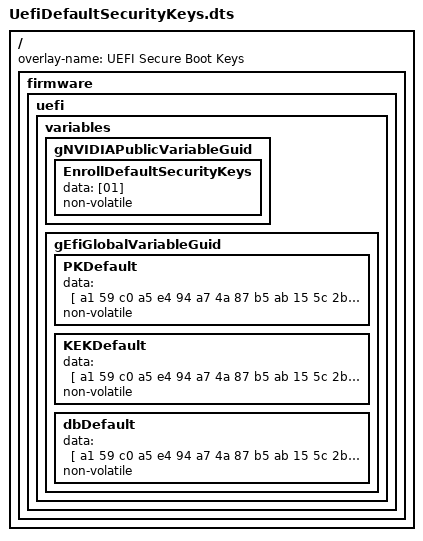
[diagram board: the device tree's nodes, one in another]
/** @file
*
*  Copyright (c) 2023, NVIDIA CORPORATION & AFFILIATES. All rights reserved.
*
*  SPDX-License-Identifier: BSD-2-Clause-Patent
*
**/
/dts-v1/;
/plugin/;
/ {
    overlay-name = "UEFI Secure Boot Keys";
    fragment@0 {
        target-path = "/";
        board_config {
            sw-modules = "uefi";
        };
        __overlay__ {
            firmware {
                uefi {
                    variables {
                        gNVIDIAPublicVariableGuid {
                            EnrollDefaultSecurityKeys {
                                data = [01];
                                non-volatile;
                            };
                        };
                        gEfiGlobalVariableGuid {
                            PKDefault {
                                data = [
 a1 59 c0 a5 e4 94 a7 4a 87 b5 ab 15 5c 2b f0 72
 49 03 00 00 00 00 00 00 2d 03 00 00 da 84 00 ee
 b6 30 6a 48 b9 b4 d8 10 9c 4b 51 21 30 82 03 19
 30 82 02 01 a0 03 02 01 02 02 14 23 b3 eb 03 c1
 76 06 ab dc ac a5 09 25 4c 3b 5f ee 77 9c 3c 30
 0d 06 09 2a 86 48 86 f7 0d 01 01 0b 05 00 30 1c
 31 1a 30 18 06 03 55 04 03 0c 11 4e 6f 6f 62 20
 50 6c 61 74 66 6f 72 6d 20 4b 65 79 30 1e 17 0d
 32 36 30 35 30 33 31 34 33 30 31 36 5a 17 0d 33
 36 30 34 33 30 31 34 33 30 31 36 5a 30 1c 31 1a
 30 18 06 03 55 04 03 0c 11 4e 6f 6f 62 20 50 6c
 61 74 66 6f 72 6d 20 4b 65 79 30 82 01 22 30 0d
 06 09 2a 86 48 86 f7 0d 01 01 01 05 00 03 82 01
 0f 00 30 82 01 0a 02 82 01 01 00 d2 66 da 04 90
 60 06 22 c6 c7 86 8f 3f 70 e8 04 f9 8a 55 e7 61
 98 74 93 7e 84 1c 29 98 27 70 31 66 c8 f6 50 54
 2d 47 d2 bc d8 2f 97 ea a3 d8 37 67 f9 31 7d 2a
 fc e8 7f f4 03 c2 41 ac 2c ee 02 c8 0e 3d b4 e5
 75 69 b4 15 8b cd 4d bc 04 f2 c7 15 8c b0 e3 30
 33 a2 d8 3a 77 1e b6 fe 5f 28 e7 5f 11 0e 53 71
 d0 aa d7 0d 21 1f 99 ba 5c 68 00 ee 5a 67 f2 5d
 a8 17 33 79 1f a8 61 29 6f da 71 60 94 7a 60 e2
 4d cd 98 c0 d9 e6 fe d2 17 d0 d5 be 4d d9 3c 82
 31 2a 14 fa eb 4c ff 08 1e dc f5 0f ae 36 f7 51
 86 46 18 dc 98 20 fe d9 e2 49 c7 52 2d 9f ac 87
 4f aa 0e c4 e0 15 24 95 06 80 b0 0f 45 52 6f c2
 9f 97 58 9d de 3d 69 d8 04 1b 94 ae 63 1d 5f 6f
 5e b4 13 a4 b6 d0 b3 e0 26 9a 37 3b 64 8f fc 10
 7c cd 79 74 76 cb a1 25 a5 ee 40 c2 fb b9 22 50
 fd 96 ef e0 4e 76 88 af 91 a9 b5 02 03 01 00 01
 a3 53 30 51 30 1d 06 03 55 1d 0e 04 16 04 14 2c
 b2 34 b0 45 06 12 fc 43 c5 42 d1 da aa 3b e2 a8
 25 1f ae 30 1f 06 03 55 1d 23 04 18 30 16 80 14
 2c b2 34 b0 45 06 12 fc 43 c5 42 d1 da aa 3b e2
 a8 25 1f ae 30 0f 06 03 55 1d 13 01 01 ff 04 05
 30 03 01 01 ff 30 0d 06 09 2a 86 48 86 f7 0d 01
 01 0b 05 00 03 82 01 01 00 2d 4a b1 95 ae 54 cc
 f6 bd 2d 67 64 11 47 99 49 74 3c 62 eb 63 90 fa
 fb be 49 59 72 c2 70 95 a8 67 d3 dd 44 59 e0 c3
 f1 a2 d8 bd e2 a4 85 82 97 8d 0a d6 3d 1d 78 33
 50 1e 5f 73 8d 74 55 af 61 6e fc f7 11 8c 46 34
 b2 46 d0 ba 0c a2 72 f6 0b 86 12 68 ed 45 49 3e
 ad 24 d2 07 51 db 90 e9 c4 8c eb 93 ec ff 3d 34
 9c d2 14 cb fb 66 e9 c0 b9 c6 77 4b bc 50 3b 22
 b1 e1 54 ee 14 b0 59 68 c4 4c 89 c0 bf 81 d8 e9
 7f 1b 9e 22 08 a6 d2 c5 f8 f0 d9 31 5e f5 82 b2
 33 f9 21 b0 93 13 6b 66 b1 69 ea d1 d5 1a 0b 5b
 db b2 6e f4 d3 7b d9 8d 90 65 92 4c 11 5e ad 52
 4d e4 93 2a 8a 86 e5 1f 70 b9 c1 72 eb eb a2 ad
 03 8e d5 16 79 b9 d7 70 61 33 12 43 db 86 09 4a
 f4 4d 6d d1 ee ba 5e 59 c8 d7 14 93 81 f7 b2 ac
 df 47 aa a9 5c b3 24 10 e0 17 0e 03 67 7c 9d 16
 49 ab ff 6b c3 b5 53 3a 55
                                ];
                                non-volatile;
                            };
                            KEKDefault {
                                data = [
 a1 59 c0 a5 e4 94 a7 4a 87 b5 ab 15 5c 2b f0 72
 51 03 00 00 00 00 00 00 35 03 00 00 da 84 00 ee
 b6 30 6a 48 b9 b4 d8 10 9c 4b 51 21 30 82 03 21
 30 82 02 09 a0 03 02 01 02 02 14 60 20 7e 3d a5
 e5 0a 19 d7 74 30 42 7b 8f 92 8f bd 69 50 f7 30
 0d 06 09 2a 86 48 86 f7 0d 01 01 0b 05 00 30 20
 31 1e 30 1c 06 03 55 04 03 0c 15 4e 6f 6f 62 20
 4b 65 79 20 45 78 63 68 61 6e 67 65 20 4b 65 79
 30 1e 17 0d 32 36 30 35 30 33 31 34 33 30 34 36
 5a 17 0d 33 36 30 34 33 30 31 34 33 30 34 36 5a
 30 20 31 1e 30 1c 06 03 55 04 03 0c 15 4e 6f 6f
 62 20 4b 65 79 20 45 78 63 68 61 6e 67 65 20 4b
 65 79 30 82 01 22 30 0d 06 09 2a 86 48 86 f7 0d
 01 01 01 05 00 03 82 01 0f 00 30 82 01 0a 02 82
 01 01 00 c7 86 bc a3 e4 9c 43 98 ee 68 c8 f2 78
 a4 78 0f c8 9d 5c 87 58 65 f2 43 68 70 2c 76 ee
 99 ff 48 76 16 f8 12 25 1b aa 44 46 c8 f5 c4 35
 b2 9d c6 30 2d 64 dd 6b 39 d6 3b d6 9f 06 95 a2
 e8 0c f3 ce ac 0a 35 6d 72 4f e3 0e b1 1e 77 4f
 1d e8 0d 18 18 df c9 c9 77 ab b1 e5 e7 ce 49 87
 e2 b0 07 ec 06 1b 14 a4 8d 35 29 bd 74 24 93 ea
 b9 c1 7e 32 9e 5e b8 20 02 eb 85 cd f0 d7 1f d6
 1a 33 4c c7 2c 40 c4 b7 77 2d 7f 0c c5 28 c5 aa
 5d 8c d6 88 65 cb 5b 89 b3 8f 25 47 a7 34 66 31
 86 8b c7 fb 5c f3 4e d6 22 70 b4 c4 38 50 38 68
 17 72 00 73 2e 1a 87 32 28 89 bd 3d bd af 0b c6
 16 aa 83 e2 f2 5b 92 d0 af 85 e8 13 bc fb 34 e8
 39 53 e9 9c 6f 24 72 fb fc 54 68 ea 00 1e 13 70
 73 ba ab 50 ff fe 2e e9 5a f0 16 a7 7c 01 3a 92
 5f 42 95 b2 2f ca 1b 3f 00 39 55 e4 65 48 4f f8
 da 5e 33 02 03 01 00 01 a3 53 30 51 30 1d 06 03
 55 1d 0e 04 16 04 14 62 5c 6c 1d 04 06 86 d0 a1
 d3 97 d6 d6 b8 dd 79 33 ca ed 6a 30 1f 06 03 55
 1d 23 04 18 30 16 80 14 62 5c 6c 1d 04 06 86 d0
 a1 d3 97 d6 d6 b8 dd 79 33 ca ed 6a 30 0f 06 03
 55 1d 13 01 01 ff 04 05 30 03 01 01 ff 30 0d 06
 09 2a 86 48 86 f7 0d 01 01 0b 05 00 03 82 01 01
 00 42 05 97 59 ff 7b 21 e9 99 4b 20 df 1b ea e8
 81 5d 5b 16 40 33 28 a4 eb a4 f1 90 68 2c 2a 6b
 66 5c f1 eb 4c 07 4f dd db 36 8a 9b b6 5e fd 7c
 60 8a 6f 90 e3 41 8d 77 79 6e 67 4f 50 5f bf 07
 7d 00 ba 72 a7 7a 7a 03 a4 81 22 18 2f 41 d0 95
 6c 3a 73 f9 65 94 b6 c5 90 3b a4 58 2b e2 8d d3
 d9 79 7e e1 46 7d f2 d2 76 50 65 a1 c6 9f 1a 8f
 c1 7e 60 82 b9 7b df a3 4c 6d 45 36 e5 ec d0 c0
 73 c2 88 4c 38 0e ab e1 d3 48 33 5d 33 15 00 16
 b2 67 50 d8 a8 81 84 28 85 bc ff 33 59 0b d6 ff
 34 05 3e f7 ff 5b 21 3a ff 96 08 e9 93 b5 de 5e
 0a 9a ed e4 c8 d5 07 31 8f 26 9c ee 99 e1 e1 f2
 f1 70 3e 66 4f 57 91 a7 4e 26 01 3c da 77 1a 9b
 16 99 f2 d3 1c 5d 3d b0 e3 e3 28 73 75 3f ac f1
 dd e7 04 4e f0 ab a7 9a 25 99 70 09 e6 55 78 03
 a1 63 ac c0 63 a9 e2 0e 64 ed 01 2b e9 63 6b 06
 cd
                                ];
                                non-volatile;
                            };
                            dbDefault {
                                data = [
 a1 59 c0 a5 e4 94 a7 4a 87 b5 ab 15 5c 2b f0 72
 5d 03 00 00 00 00 00 00 41 03 00 00 da 84 00 ee
 b6 30 6a 48 b9 b4 d8 10 9c 4b 51 21 30 82 03 2d
 30 82 02 15 a0 03 02 01 02 02 14 67 49 d6 ec 9d
 ea a8 f4 89 f6 e6 99 8a 87 c4 d9 e1 cb 83 87 30
 0d 06 09 2a 86 48 86 f7 0d 01 01 0b 05 00 30 26
 31 24 30 22 06 03 55 04 03 0c 1b 4e 6f 6f 62 20
 53 69 67 6e 61 74 75 72 65 20 44 61 74 61 62 61
 73 65 20 6b 65 79 30 1e 17 0d 32 36 30 35 30 33
 31 34 33 31 31 35 5a 17 0d 33 36 30 34 33 30 31
 34 33 31 31 35 5a 30 26 31 24 30 22 06 03 55 04
 03 0c 1b 4e 6f 6f 62 20 53 69 67 6e 61 74 75 72
 65 20 44 61 74 61 62 61 73 65 20 6b 65 79 30 82
 01 22 30 0d 06 09 2a 86 48 86 f7 0d 01 01 01 05
 00 03 82 01 0f 00 30 82 01 0a 02 82 01 01 00 bd
 89 4b 55 b3 de 2b fc 4d 5d a6 a7 83 c9 a3 ec e2
 27 38 d5 fd 55 5d 5d 9f 8d 23 99 4f b8 44 fd 2a
 8f f9 a7 8c 4c 23 5c f7 bb 64 6f 18 7b 48 02 91
 01 4b 9e 87 eb 0a e6 40 3c 71 57 9f e8 89 a9 54
 0b f7 11 d4 3a 2e 42 a1 1a a5 30 44 f0 b4 82 80
 d9 8e 0b 62 6b 04 42 b9 b1 b2 60 3c 83 e9 a6 f6
 7e cc 9d 22 f0 95 90 9d 6a 7c b1 ce ed e6 0f a4
 3a 80 d0 59 7c d7 06 d5 29 15 41 7d d9 ea 32 90
 2d 14 62 0b ea 8e ed 86 06 47 3f f0 03 44 46 67
 cd 85 04 7a 82 a5 3f 62 f0 fe a5 4f c2 05 0a f2
 f6 c7 61 83 6a 6d b9 d5 e4 8f b2 03 a3 f4 4b 9a
 93 62 5b 48 d9 cf ee 1c 1a cc 03 b6 f0 1a d1 61
 01 70 fa 12 3f e2 ff f7 6a 37 e0 25 47 58 15 e5
 31 41 ea fc 73 2d c8 70 eb 40 d7 74 12 c7 80 d1
 e7 8d f6 c4 f7 e5 47 34 de 00 ad 46 a6 89 90 04
 77 37 29 83 6a 72 de f8 1c 96 76 84 80 f8 89 02
 03 01 00 01 a3 53 30 51 30 1d 06 03 55 1d 0e 04
 16 04 14 97 c5 71 11 29 29 d3 82 86 c0 40 f9 2a
 ee 94 4b 30 d0 ac 04 30 1f 06 03 55 1d 23 04 18
 30 16 80 14 97 c5 71 11 29 29 d3 82 86 c0 40 f9
 2a ee 94 4b 30 d0 ac 04 30 0f 06 03 55 1d 13 01
 01 ff 04 05 30 03 01 01 ff 30 0d 06 09 2a 86 48
 86 f7 0d 01 01 0b 05 00 03 82 01 01 00 ad 5e 08
 1b 67 d4 91 87 85 b5 22 a4 05 d7 c9 77 f7 5c 25
 fc 15 0e f9 63 0b e5 60 54 9f 52 90 a9 a0 30 0d
 56 f4 54 eb 62 99 8d f9 9f 24 eb 22 6b 5e fc 3d
 e6 81 34 6f a6 99 bf 78 fd 71 12 e0 fc 2f cb 4d
 d2 1f 80 57 db d5 e4 f8 b8 18 9c 4a 46 e7 28 2a
 52 86 05 03 d3 2b 52 d5 35 dd 43 48 2d 9b 28 f3
 d3 54 fc 62 12 71 de 38 73 91 c9 21 14 65 c6 86
 7c 85 f7 5e d7 d1 20 2e 89 58 6f 6e 2f b0 6f 7a
 11 ff b5 2d b0 a3 35 c0 e3 2a 25 5a f3 bd 82 38
 ca dc 55 9b b1 77 0c 1c 35 4e a8 fb fb 37 25 1e
 ec 32 0c 71 29 26 a2 56 9b 92 af 49 00 b9 15 e1
 35 d3 7f e3 d5 2b 76 b6 0c ee 7b 56 b4 12 26 95
 2f cb 3c 8d 43 58 a5 e6 e8 bf 5a 55 e2 dc 3a 09
 e9 da b3 69 d6 91 9f 89 3a 60 37 aa f1 9e 0c 0c
 f8 d1 4a e5 a8 53 be 75 30 75 35 91 9f a2 d2 bf
 43 d7 82 f8 79 5c a7 ee fd 10 49 ab 10
                                ];
                                non-volatile;
                            };
                        };
                    };
                };
            };
        };
    };
};
